# NPCX490M register map
File version: 1.0
Registers are 8-bit, read-write, reset 0x0 unless marked. A register's access mark holds for its fields unless they carry their own. Offsets are from the block's base; [hi:lo] are bit positions.

## MIWU0
Base 0x400BB000
Same registers: MIWU1 0x400BD000, MIWU2 0x400BF000
0x00 WKEDGn0 — Edge Detection nx Register (WKEDGnx)
0x01 WKAEDGn0 — Any Edge Detection nx Register (WKAEDGnx)
0x02 WKMODn0 — Wake-Up Detection Mode nx Register (WKMODnx)
0x03 WKPNDn0 — Pending nx Register (WKPNDnx)
0x04 WKPCLn0 — Pending Clear nx Register (WKPCLnx)
0x05 WKENn0 — Enable nx Register (WKENnx)
0x06 WKSTn0 — Wake-Up Status nx Register (WKSTnx)
0x07 WKINENn0 — Wake-Up Input Enable nx Register (WKINENnx)
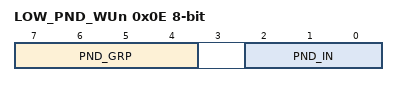
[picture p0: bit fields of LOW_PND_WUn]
0x0E LOW_PND_WUn — Lowest Pending Wake-Up Register (LOW_PND_WUn)
  [7:4] PND_GRP — Pending Group
  [2:0] PND_IN — Pending Input
0x10 WKEDGn2 — Edge Detection nx Register (WKEDGnx)
0x11 WKAEDGn2 — Any Edge Detection nx Register (WKAEDGnx)
0x12 WKMODn2 — Wake-Up Detection Mode nx Register (WKMODnx)
0x13 WKPNDn2 — Pending nx Register (WKPNDnx)
0x14 WKPCLn2 — Pending Clear nx Register (WKPCLnx)
0x15 WKENn2 — Enable nx Register (WKENnx)
0x16 WKSTn2 — Wake-Up Status nx Register (WKSTnx)
0x17 WKINENn2 — Wake-Up Input Enable nx Register (WKINENnx)
0x20 WKEDGn4 — Edge Detection nx Register (WKEDGnx)
0x21 WKAEDGn4 — Any Edge Detection nx Register (WKAEDGnx)
0x22 WKMODn4 — Wake-Up Detection Mode nx Register (WKMODnx)
0x23 WKPNDn4 — Pending nx Register (WKPNDnx)
0x24 WKPCLn4 — Pending Clear nx Register (WKPCLnx)
0x25 WKENn4 — Enable nx Register (WKENnx)
0x26 WKSTn4 — Wake-Up Status nx Register (WKSTnx)
0x27 WKINENn4 — Wake-Up Input Enable nx Register (WKINENnx)
0x30 WKEDGn6 — Edge Detection nx Register (WKEDGnx)
0x31 WKAEDGn6 — Any Edge Detection nx Register (WKAEDGnx)
0x32 WKMODn6 — Wake-Up Detection Mode nx Register (WKMODnx)
0x33 WKPNDn6 — Pending nx Register (WKPNDnx)
0x34 WKPCLn6 — Pending Clear nx Register (WKPCLnx)
0x35 WKENn6 — Enable nx Register (WKENnx)
0x36 WKSTn6 — Wake-Up Status nx Register (WKSTnx)
0x37 WKINENn6 — Wake-Up Input Enable nx Register (WKINENnx)
0x40 WKEDGn1 — Edge Detection nx Register (WKEDGnx)
0x41 WKAEDGn1 — Any Edge Detection nx Register (WKAEDGnx)
0x42 WKMODn1 — Wake-Up Detection Mode nx Register (WKMODnx)
0x43 WKPNDn1 — Pending nx Register (WKPNDnx)
0x44 WKPCLn1 — Pending Clear nx Register (WKPCLnx)
0x45 WKENn1 — Enable nx Register (WKENnx)
0x46 WKSTn1 — Wake-Up Status nx Register (WKSTnx)
0x47 WKINENn1 — Wake-Up Input Enable nx Register (WKINENnx)
0x50 WKEDGn3 — Edge Detection nx Register (WKEDGnx)
0x51 WKAEDGn3 — Any Edge Detection nx Register (WKAEDGnx)
0x52 WKMODn3 — Wake-Up Detection Mode nx Register (WKMODnx)
0x53 WKPNDn3 — Pending nx Register (WKPNDnx)
0x54 WKPCLn3 — Pending Clear nx Register (WKPCLnx)
0x55 WKENn3 — Enable nx Register (WKENnx)
0x56 WKSTn3 — Wake-Up Status nx Register (WKSTnx)
0x57 WKINENn3 — Wake-Up Input Enable nx Register (WKINENnx)
0x60 WKEDGn5 — Edge Detection nx Register (WKEDGnx)
0x61 WKAEDGn5 — Any Edge Detection nx Register (WKAEDGnx)
0x62 WKMODn5 — Wake-Up Detection Mode nx Register (WKMODnx)
0x63 WKPNDn5 — Pending nx Register (WKPNDnx)
0x64 WKPCLn5 — Pending Clear nx Register (WKPCLnx)
0x65 WKENn5 — Enable nx Register (WKENnx)
0x66 WKSTn5 — Wake-Up Status nx Register (WKSTnx)
0x67 WKINENn5 — Wake-Up Input Enable nx Register (WKINENnx)
0x70 WKEDGn7 — Edge Detection nx Register (WKEDGnx)
0x71 WKAEDGn7 — Any Edge Detection nx Register (WKAEDGnx)
0x72 WKMODn7 — Wake-Up Detection Mode nx Register (WKMODnx)
0x73 WKPNDn7 — Pending nx Register (WKPNDnx)
0x74 WKPCLn7 — Pending Clear nx Register (WKPCLnx)
0x75 WKENn7 — Enable nx Register (WKENnx)
0x76 WKSTn7 — Wake-Up Status nx Register (WKSTnx)
0x77 WKINENn7 — Wake-Up Input Enable nx Register (WKINENnx)

## MSWC
Base 0x400C1000
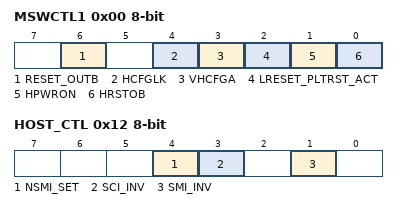
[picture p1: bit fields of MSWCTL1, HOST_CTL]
0x00 MSWCTL1 — MSWC Control Status 1 Register (MSWCTL1)
  [6] RESET_OUTB — RESET_OUT Control Bit
  [4] HCFGLK — Host Configuration Address Lock
  [3] VHCFGA — Valid Host Configuration Address
  [2] LRESET_PLTRST_ACT — LRESET or PLTRST Active
  [1] HPWRON — Host Power-On
  [0] HRSTOB — Host Reset Control Bit
0x08 HCBAL — Host Configuration Base Address Low Register (HCBAL)
0x0A HCBAH — Host Configuration Base Address High Register (HCBAH)
0x12 HOST_CTL — Host Control Register (HOST_CTL)
  [4] NSMI_SET — SMI Level Set
  [3] SCI_INV — EC_SCI Invert
  [1] SMI_INV — SMI Invert
0x1C SRID_CR — SRID Core Access Register (SRID_CR)
0x20 SID_CR — SID Core Access Register (SID_CR)
0x22 DEVICE_ID_CR — DEVICE_ID Core Access Register (DEVICE_ID_CR)
0x28 CHPREV_CR — Chip Revision Core Access Register (CHPREV_CR)
